# ioat91sam3s2 register map
Registers are 32-bit, access not given, no defined reset value unless marked. A register's access mark holds for its fields unless they carry their own. Addresses are absolute; registers are grouped by the start of their names; [hi:lo] are bit positions; {n}, {i} and the like mark numbered series; 'fields as' and 'values as' point back to an identical list.

## UDP
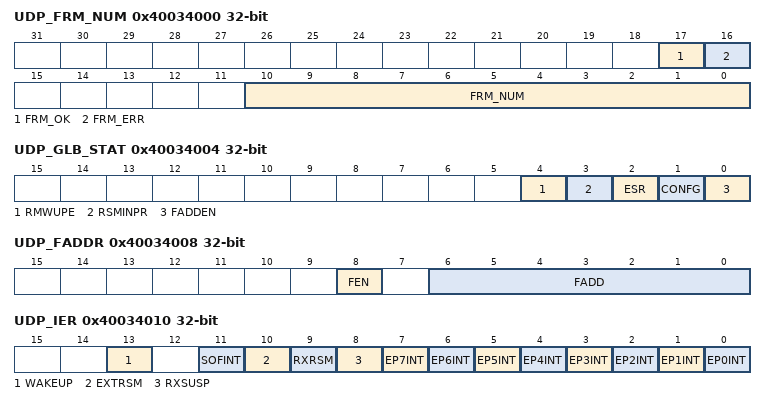
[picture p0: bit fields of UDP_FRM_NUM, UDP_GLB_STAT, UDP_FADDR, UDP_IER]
0x40034000 UDP_FRM_NUM
  [17] FRM_OK, [16] FRM_ERR, [10:0] FRM_NUM
0x40034004 UDP_GLB_STAT
  [4] RMWUPE, [3] RSMINPR, [2] ESR, [1] CONFG, [0] FADDEN
0x40034008 UDP_FADDR
  [8] FEN, [6:0] FADD
0x40034010 UDP_IER
  [13] WAKEUP, [11] SOFINT, [10] EXTRSM, [9] RXRSM, [8] RXSUSP, [n] EP{n}INT (n=0..7)
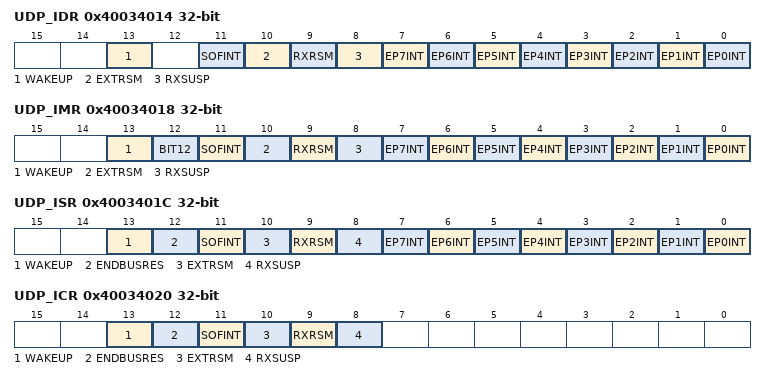
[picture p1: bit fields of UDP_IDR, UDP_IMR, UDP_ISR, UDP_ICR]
0x40034014 UDP_IDR
  fields as UDP_IER
0x40034018 UDP_IMR
  [13] WAKEUP, [12] BIT12, [11] SOFINT, [10] EXTRSM, [9] RXRSM, [8] RXSUSP, [n] EP{n}INT (n=0..7)
0x4003401C UDP_ISR
  [13] WAKEUP, [12] ENDBUSRES, [11] SOFINT, [10] EXTRSM, [9] RXRSM, [8] RXSUSP, [n] EP{n}INT (n=0..7)
0x40034020 UDP_ICR
  [13] WAKEUP, [12] ENDBUSRES, [11] SOFINT, [10] EXTRSM, [9] RXRSM, [8] RXSUSP
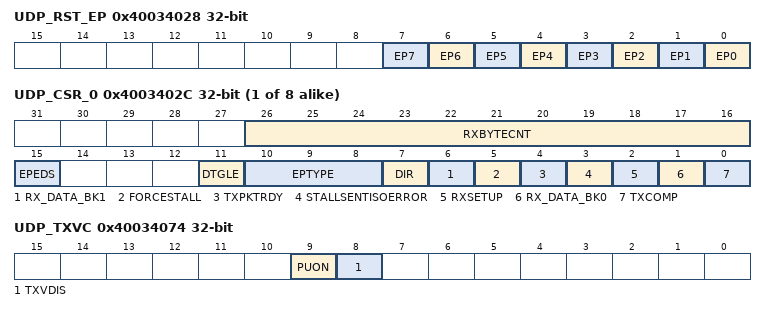
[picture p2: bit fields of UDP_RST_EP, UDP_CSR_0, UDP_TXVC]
0x40034028 UDP_RST_EP
  [n] EP{n} (n=0..7)
0x4003402C UDP_CSR_{i} (i=0..7)
  [26:16] RXBYTECNT, [15] EPEDS, [11] DTGLE, [10:8] EPTYPE, [7] DIR, [6] RX_DATA_BK1, [5] FORCESTALL, [4] TXPKTRDY, [3] STALLSENTISOERROR, [2] RXSETUP, [1] RX_DATA_BK0, [0] TXCOMP
0x4003404C UDP_FDR_{i} (i=0..7)
  [7:0] FIFO_DATA
0x40034074 UDP_TXVC
  [9] PUON, [8] TXVDIS

## ADC
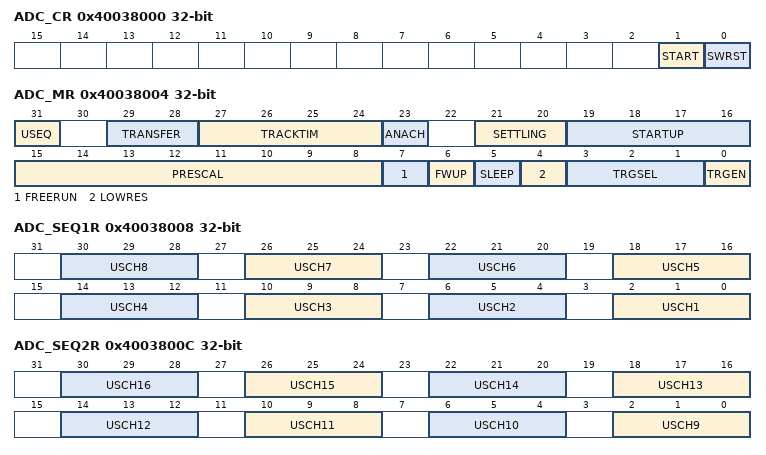
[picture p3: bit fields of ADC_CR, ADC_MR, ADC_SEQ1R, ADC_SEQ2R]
0x40038000 ADC_CR
  [1] START, [0] SWRST
0x40038004 ADC_MR
  [31] USEQ, [29:28] TRANSFER, [27:24] TRACKTIM, [23] ANACH, [21:20] SETTLING, [19:16] STARTUP, [15:8] PRESCAL, [7] FREERUN, [6] FWUP, [5] SLEEP, [4] LOWRES, [3:1] TRGSEL, [0] TRGEN
0x40038008 ADC_SEQ1R
  [4n-2:4n-4] USCH{n} (n=1..8)
0x4003800C ADC_SEQ2R
  [4n-34:4n-36] USCH{n} (n=9..16)
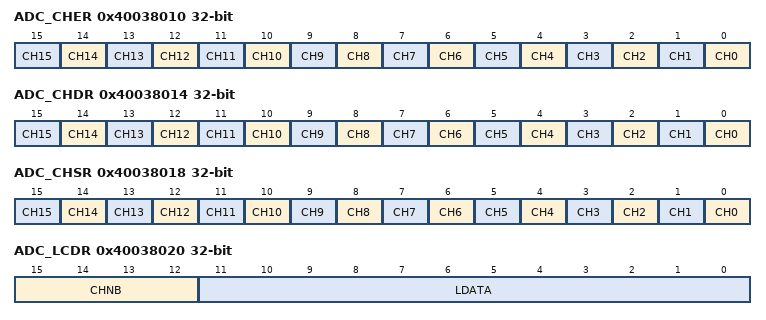
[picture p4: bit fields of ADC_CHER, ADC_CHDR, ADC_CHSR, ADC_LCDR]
0x40038010 ADC_CHER
  [n] CH{n} (n=0..15)
0x40038014 ADC_CHDR
  [n] CH{n} (n=0..15)
0x40038018 ADC_CHSR
  [n] CH{n} (n=0..15)
0x40038020 ADC_LCDR
  [15:12] CHNB, [11:0] LDATA
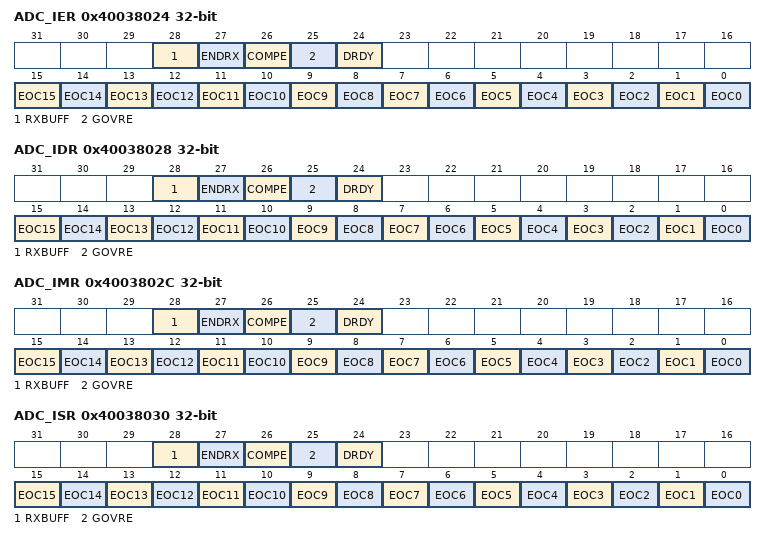
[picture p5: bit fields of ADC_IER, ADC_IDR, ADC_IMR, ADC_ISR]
0x40038024 ADC_IER
  [28] RXBUFF, [27] ENDRX, [26] COMPE, [25] GOVRE, [24] DRDY, [n] EOC{n} (n=0..15)
0x40038028 ADC_IDR
  fields as ADC_IER
0x4003802C ADC_IMR
  fields as ADC_IER
0x40038030 ADC_ISR
  fields as ADC_IER
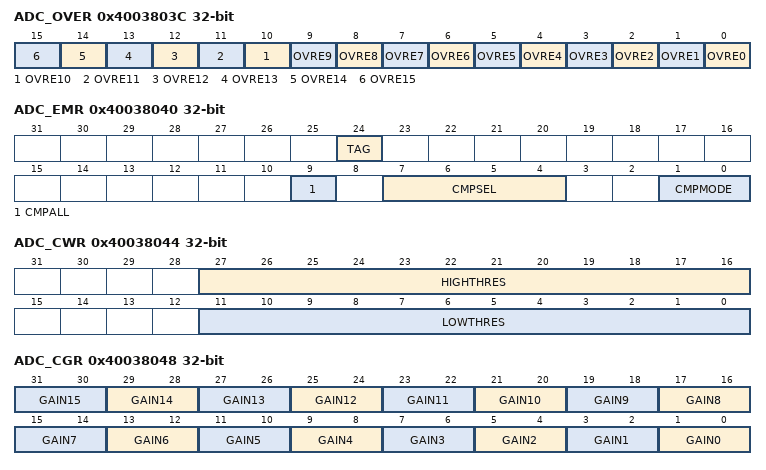
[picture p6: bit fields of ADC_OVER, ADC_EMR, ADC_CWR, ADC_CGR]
0x4003803C ADC_OVER
  [n] OVRE{n} (n=0..15)
0x40038040 ADC_EMR
  [24] TAG, [9] CMPALL, [7:4] CMPSEL, [1:0] CMPMODE
0x40038044 ADC_CWR
  [27:16] HIGHTHRES, [11:0] LOWTHRES
0x40038048 ADC_CGR
  [2n+1:2n] GAIN{n} (n=0..15)
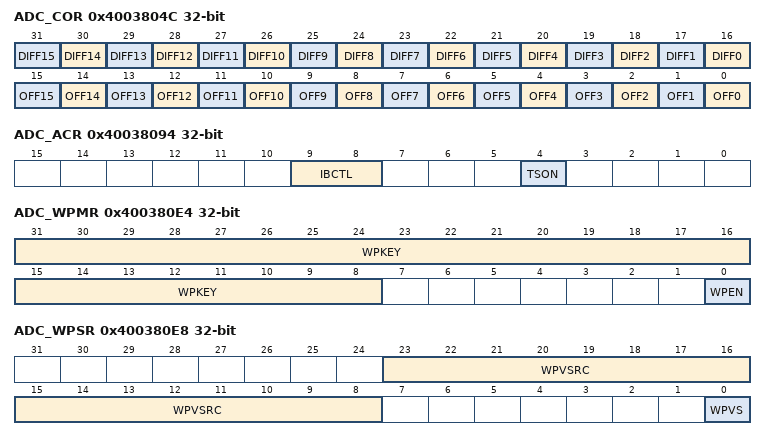
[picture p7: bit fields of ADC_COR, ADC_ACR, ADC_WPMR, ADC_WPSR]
0x4003804C ADC_COR
  [n+16] DIFF{n} (n=0..15), [n] OFF{n} (n=0..15)
{0x40038050+4i} ADC_CDR{i} (i=0..6)
  [9:0] DATA
0x4003806C ADC_CDR15
  [9:0] DATA
0x40038094 ADC_ACR
  [9:8] IBCTL, [4] TSON
0x400380E4 ADC_WPMR
  [31:8] WPKEY, [0] WPEN
0x400380E8 ADC_WPSR
  [23:8] WPVSRC, [0] WPVS
0x40038100 ADC_RPR
  [31:0] RXPTR
0x40038104 ADC_RCR
  [15:0] RXCTR
0x40038108 ADC_TPR
  [31:0] TXPTR
0x4003810C ADC_TCR
  [15:0] TXCTR
0x40038110 ADC_RNPR
  [31:0] RXNPTR
0x40038114 ADC_RNCR
  [15:0] RXNCTR
0x40038118 ADC_TNPR
  [31:0] TXNPTR
0x4003811C ADC_TNCR
  [15:0] TXNCTR
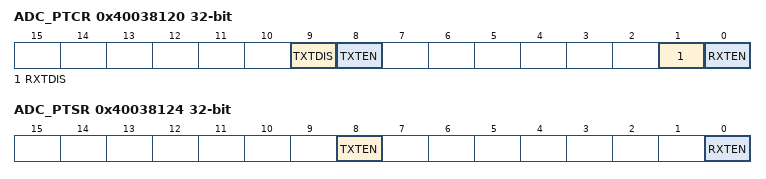
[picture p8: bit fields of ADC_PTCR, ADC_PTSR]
0x40038120 ADC_PTCR
  [9] TXTDIS, [8] TXTEN, [1] RXTDIS, [0] RXTEN
0x40038124 ADC_PTSR
  [8] TXTEN, [0] RXTEN

## DACC
0x4003C000 DACC_CR
  [0] SWRST
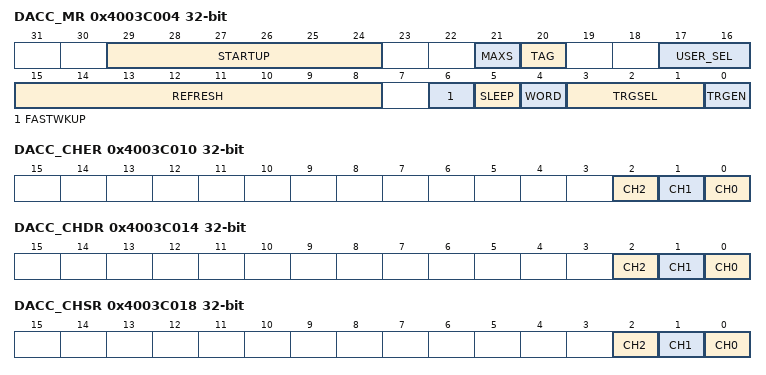
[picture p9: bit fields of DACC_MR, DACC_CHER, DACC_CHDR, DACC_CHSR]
0x4003C004 DACC_MR
  [29:24] STARTUP, [21] MAXS, [20] TAG, [17:16] USER_SEL, [15:8] REFRESH, [6] FASTWKUP, [5] SLEEP, [4] WORD, [3:1] TRGSEL, [0] TRGEN
0x4003C010 DACC_CHER
  [2] CH2, [1] CH1, [0] CH0
0x4003C014 DACC_CHDR
  [2] CH2, [1] CH1, [0] CH0
0x4003C018 DACC_CHSR
  [2] CH2, [1] CH1, [0] CH0
0x4003C020 DACC_CDR
  [31:0] DATA
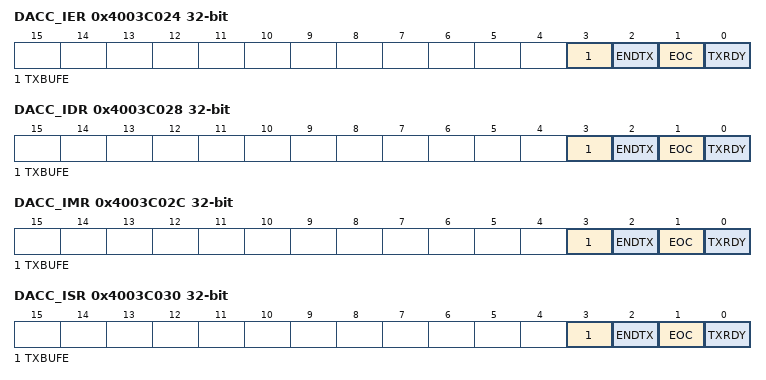
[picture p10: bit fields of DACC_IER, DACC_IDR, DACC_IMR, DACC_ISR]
0x4003C024 DACC_IER
  [3] TXBUFE, [2] ENDTX, [1] EOC, [0] TXRDY
0x4003C028 DACC_IDR
  [3] TXBUFE, [2] ENDTX, [1] EOC, [0] TXRDY
0x4003C02C DACC_IMR
  [3] TXBUFE, [2] ENDTX, [1] EOC, [0] TXRDY
0x4003C030 DACC_ISR
  [3] TXBUFE, [2] ENDTX, [1] EOC, [0] TXRDY
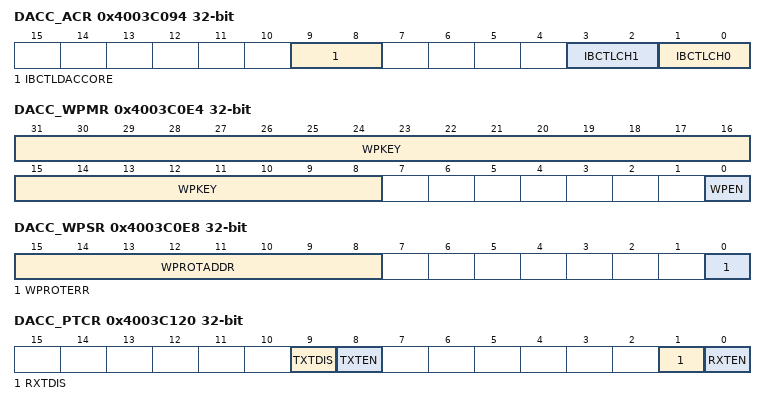
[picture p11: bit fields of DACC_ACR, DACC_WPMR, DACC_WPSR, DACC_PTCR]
0x4003C094 DACC_ACR
  [9:8] IBCTLDACCORE, [3:2] IBCTLCH1, [1:0] IBCTLCH0
0x4003C0E4 DACC_WPMR
  [31:8] WPKEY, [0] WPEN
0x4003C0E8 DACC_WPSR
  [15:8] WPROTADDR, [0] WPROTERR
0x4003C100 DACC_RPR
  [31:0] RXPTR
0x4003C104 DACC_RCR
  [15:0] RXCTR
0x4003C108 DACC_TPR
  [31:0] TXPTR
0x4003C10C DACC_TCR
  [15:0] TXCTR
0x4003C110 DACC_RNPR
  [31:0] RXNPTR
0x4003C114 DACC_RNCR
  [15:0] RXNCTR
0x4003C118 DACC_TNPR
  [31:0] TXNPTR
0x4003C11C DACC_TNCR
  [15:0] TXNCTR
0x4003C120 DACC_PTCR
  [9] TXTDIS, [8] TXTEN, [1] RXTDIS, [0] RXTEN
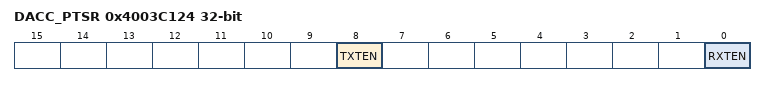
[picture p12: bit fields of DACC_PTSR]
0x4003C124 DACC_PTSR
  [8] TXTEN, [0] RXTEN
